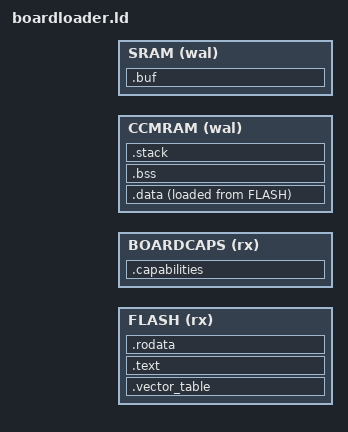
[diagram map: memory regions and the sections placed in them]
INCLUDE "./embed/trezorhal/stm32f4/linker/memory.ld";

ENTRY(reset_handler)

MEMORY {
  FLASH  (rx)     : ORIGIN = BOARDLOADER_START, LENGTH = BOARDLOADER_MAXSIZE - BOARDCAPS_MAXSIZE
  BOARDCAPS (rx)  : ORIGIN = BOARDCAPS_START, LENGTH = BOARDCAPS_MAXSIZE
  CCMRAM (wal)    : ORIGIN = MCU_CCMRAM, LENGTH = MCU_CCMRAM_SIZE
  SRAM   (wal)    : ORIGIN = MCU_SRAM, LENGTH = MCU_SRAM_SIZE
}

main_stack_base = ORIGIN(CCMRAM) + LENGTH(CCMRAM); /* 8-byte aligned full descending stack */
_sstack = ORIGIN(CCMRAM);
_estack = main_stack_base;

/* used by the startup code to populate variables used by the C code */
data_lma = LOADADDR(.data);
data_vma = ADDR(.data);
data_size = SIZEOF(.data);
bss_start = ADDR(.bss);
bss_end = ADDR(.bss) + SIZEOF(.bss);

/* used by the startup code to wipe memory */
_startup_clear_ram_0_start = MCU_CCMRAM;
_startup_clear_ram_0_end = MCU_CCMRAM + MCU_CCMRAM_SIZE;
_startup_clear_ram_1_start = MCU_SRAM;
_startup_clear_ram_1_end = MCU_SRAM + MCU_SRAM_SIZE;

/* used by the startup/jump code to wipe memory */
_handoff_clear_ram_0_start = MCU_CCMRAM;
_handoff_clear_ram_0_end = MCU_CCMRAM + MCU_CCMRAM_SIZE;
_handoff_clear_ram_1_start = MCU_SRAM;
_handoff_clear_ram_1_end = MCU_SRAM + MCU_SRAM_SIZE;

/* used by the shutdown code to wipe memory */
_shutdown_clear_ram_0_start = MCU_CCMRAM;
_shutdown_clear_ram_0_end = MCU_CCMRAM + MCU_CCMRAM_SIZE;
_shutdown_clear_ram_1_start = MCU_SRAM;
_shutdown_clear_ram_1_end = MCU_SRAM + MCU_SRAM_SIZE;

SECTIONS {
  .vector_table : ALIGN(CODE_ALIGNMENT) {
    KEEP(*(.vector_table));
  } >FLASH AT>FLASH

  .text : ALIGN(4) {
    *(.text*);
    . = ALIGN(4); /* make the section size a multiple of the word size */
  } >FLASH AT>FLASH

  .rodata : ALIGN(4) {
    *(.rodata*);
    . = ALIGN(4); /* make the section size a multiple of the word size */
  } >FLASH AT>FLASH

  .data : ALIGN(4) {
    *(.data*);
    . = ALIGN(4); /* make the section size a multiple of the word size */
  } >CCMRAM AT>FLASH

  .bss : ALIGN(4) {
    *(.bss*);
    . = ALIGN(4); /* make the section size a multiple of the word size */
  } >CCMRAM

  .buf : ALIGN(4) {
    *(.buf*);
    . = ALIGN(4);
  } >SRAM

  .capabilities : ALIGN(4) {
    KEEP(*(.capabilities_section*));
    . = ALIGN(4);
  } >BOARDCAPS

  .stack : ALIGN(8) {
    . = 4K; /* this acts as a build time assertion that at least this much memory is available for stack use */
  } >CCMRAM
}
